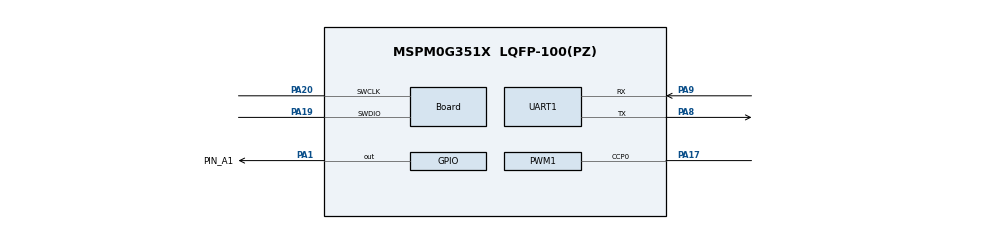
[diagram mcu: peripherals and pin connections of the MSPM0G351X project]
/**
 * @cliArgs --device "MSPM0G351X" --part "Default" --package "LQFP-100(PZ)" --product "mspm0_sdk@2.05.01.00"
 * @versions {"tool":"1.24.0+4110"}
 */

/**
 * Import the modules used in this configuration.
 */
const ADC12         = scripting.addModule("/ti/driverlib/ADC12", {}, false);
const ADC121        = ADC12.addInstance();
const ADC122        = ADC12.addInstance();
const Board         = scripting.addModule("/ti/driverlib/Board");
const DAC12         = scripting.addModule("/ti/driverlib/DAC12");
const DMA           = scripting.addModule("/ti/driverlib/DMA");
const GPIO          = scripting.addModule("/ti/driverlib/GPIO", {}, false);
const GPIO1         = GPIO.addInstance();
const GPIO2         = GPIO.addInstance();
const PWM           = scripting.addModule("/ti/driverlib/PWM", {}, false);
const PWM1          = PWM.addInstance();
const SYSCTL        = scripting.addModule("/ti/driverlib/SYSCTL");
const TIMER         = scripting.addModule("/ti/driverlib/TIMER", {}, false);
const TIMER1        = TIMER.addInstance();
const UART          = scripting.addModule("/ti/driverlib/UART", {}, false);
const UART1         = UART.addInstance();
const ProjectConfig = scripting.addModule("/ti/project_config/ProjectConfig");

/**
 * Write custom configuration values to the imported modules.
 */
const gate8  = system.clockTree["MFPCLKGATE"];
gate8.enable = true;

ADC121.$name                             = "ADC12_0";
ADC121.trigSrc                           = "DL_ADC12_TRIG_SRC_EVENT";
ADC121.subChanID                         = 1;
ADC121.hwDenominator                     = "DL_ADC12_HW_AVG_DEN_DIV_BY_128";
ADC121.adcMem0chansel                    = "DL_ADC12_INPUT_CHAN_2";
ADC121.configureDMA                      = true;
ADC121.enabledInterrupts                 = ["DL_ADC12_INTERRUPT_DMA_DONE"];
ADC121.repeatMode                        = true;
ADC121.enabledDMATriggers                = ["DL_ADC12_DMA_MEM0_RESULT_LOADED"];
ADC121.sampleTime0                       = "62.5ns";
ADC121.adcMem0trig                       = "DL_ADC12_TRIGGER_MODE_TRIGGER_NEXT";
ADC121.sampCnt                           = 1;
ADC121.powerDownMode                     = "DL_ADC12_POWER_DOWN_MODE_MANUAL";
ADC121.peripheral.$assign                = "ADC0";
ADC121.adcPin2Config.$name               = "ti_driverlib_gpio_GPIOPinGeneric0";
ADC121.DMA_CHANNEL.$name                 = "DMA_CH0";
ADC121.DMA_CHANNEL.srcLength             = "HALF_WORD";
ADC121.DMA_CHANNEL.dstLength             = "HALF_WORD";
ADC121.DMA_CHANNEL.addressMode           = "f2b";
ADC121.DMA_CHANNEL.configureTransferSize = true;
ADC121.DMA_CHANNEL.transferSize          = 1024;

ADC122.$name                             = "ADC12_1";
ADC122.trigSrc                           = "DL_ADC12_TRIG_SRC_EVENT";
ADC122.hwDenominator                     = "DL_ADC12_HW_AVG_DEN_DIV_BY_32";
ADC122.subChanID                         = 2;
ADC122.adcMem0chansel                    = "DL_ADC12_INPUT_CHAN_14";
ADC122.powerDownMode                     = "DL_ADC12_POWER_DOWN_MODE_MANUAL";
ADC122.sampleTime0                       = "62.5ns";
ADC122.enabledInterrupts                 = ["DL_ADC12_INTERRUPT_DMA_DONE"];
ADC122.configureDMA                      = true;
ADC122.adcMem0trig                       = "DL_ADC12_TRIGGER_MODE_TRIGGER_NEXT";
ADC122.sampCnt                           = 1;
ADC122.enabledDMATriggers                = ["DL_ADC12_DMA_MEM0_RESULT_LOADED"];
ADC122.repeatMode                        = true;
ADC122.peripheral.$assign                = "ADC1";
ADC122.peripheral.adcPin14.$assign       = "PB27";
ADC122.adcPin14Config.$name              = "ti_driverlib_gpio_GPIOPinGeneric1";
ADC122.DMA_CHANNEL.$name                 = "DMA_CH1";
ADC122.DMA_CHANNEL.srcLength             = "HALF_WORD";
ADC122.DMA_CHANNEL.dstLength             = "HALF_WORD";
ADC122.DMA_CHANNEL.addressMode           = "f2b";
ADC122.DMA_CHANNEL.configureTransferSize = true;
ADC122.DMA_CHANNEL.transferSize          = 1024;

Board.peripheral.$assign          = "DEBUGSS";
Board.peripheral.swclkPin.$assign = "PA20";
Board.peripheral.swdioPin.$assign = "PA19";

DAC12.dacAmplifier       = "ON";
DAC12.dacOutputPinEn     = true;
DAC12.dacSampleTimerEn   = true;
DAC12.dacFIFOTrigger     = "HWTRIG0";
DAC12.peripheral.$assign = "DAC0";
DAC12.OutPinConfig.$name = "ti_driverlib_gpio_GPIOPinGeneric5";

GPIO1.$name                           = "GPIO_AD9910";
GPIO1.associatedPins.create(12);
GPIO1.associatedPins[0].$name         = "PIN_RESET";
GPIO1.associatedPins[0].assignedPort  = "PORTB";
GPIO1.associatedPins[0].assignedPin   = "2";
GPIO1.associatedPins[1].$name         = "PIN_CS";
GPIO1.associatedPins[1].assignedPort  = "PORTA";
GPIO1.associatedPins[1].assignedPin   = "31";
GPIO1.associatedPins[2].$name         = "PIN_SCLK";
GPIO1.associatedPins[2].assignedPort  = "PORTA";
GPIO1.associatedPins[2].assignedPin   = "29";
GPIO1.associatedPins[3].$name         = "PIN_SDIO";
GPIO1.associatedPins[3].assignedPort  = "PORTC";
GPIO1.associatedPins[3].assignedPin   = "17";
GPIO1.associatedPins[4].$name         = "PIN_UPDATE";
GPIO1.associatedPins[4].assignedPort  = "PORTC";
GPIO1.associatedPins[4].assignedPin   = "26";
GPIO1.associatedPins[5].$name         = "PIN_PROFILE0";
GPIO1.associatedPins[5].assignedPort  = "PORTC";
GPIO1.associatedPins[5].assignedPin   = "27";
GPIO1.associatedPins[6].$name         = "PIN_PROFILE1";
GPIO1.associatedPins[6].assignedPort  = "PORTC";
GPIO1.associatedPins[6].assignedPin   = "7";
GPIO1.associatedPins[7].$name         = "PIN_PROFILE2";
GPIO1.associatedPins[7].assignedPort  = "PORTB";
GPIO1.associatedPins[7].assignedPin   = "17";
GPIO1.associatedPins[8].$name         = "PIN_DRCTL";
GPIO1.associatedPins[8].assignedPort  = "PORTB";
GPIO1.associatedPins[8].assignedPin   = "19";
GPIO1.associatedPins[9].assignedPort  = "PORTA";
GPIO1.associatedPins[9].assignedPin   = "21";
GPIO1.associatedPins[9].$name         = "PIN_DRHOLD";
GPIO1.associatedPins[10].assignedPort = "PORTA";
GPIO1.associatedPins[10].assignedPin  = "22";
GPIO1.associatedPins[10].$name        = "PIN_PWR";
GPIO1.associatedPins[11].$name        = "PIN_OSK";
GPIO1.associatedPins[11].assignedPort = "PORTB";
GPIO1.associatedPins[11].assignedPin  = "16";

GPIO2.$name                         = "GPIO_KEY";
GPIO2.associatedPins[0].$name       = "PIN_A1";
GPIO2.associatedPins[0].pin.$assign = "PA1";

PWM1.$name                      = "PWM_0";
PWM1.ccIndex                    = [0];
PWM1.PWM_CHANNEL_0.$name        = "ti_driverlib_pwm_PWMTimerCC0";
PWM1.ccp0PinConfig.$name        = "ti_driverlib_gpio_GPIOPinGeneric4";
PWM1.peripheral.$assign         = "TIMA1";
PWM1.peripheral.ccp0Pin.$assign = "PA17";

SYSCTL.forceDefaultClkConfig = true;
SYSCTL.MFPCLKEn              = true;

TIMER1.$name                       = "TIMER_0";
TIMER1.event1PublisherChannel      = 1;
TIMER1.event1ControllerInterruptEn = ["ZERO_EVENT"];
TIMER1.event2PublisherChannel      = 2;
TIMER1.event2ControllerInterruptEn = ["ZERO_EVENT"];
TIMER1.timerMode                   = "PERIODIC";
TIMER1.timerPeriod                 = "1us";
TIMER1.peripheral.$assign          = "TIMG0";

UART1.$name                    = "UART_0";
UART1.enabledInterrupts        = ["RX"];
UART1.peripheral.rxPin.$assign = "PA9";
UART1.peripheral.txPin.$assign = "PA8";
UART1.txPinConfig.$name        = "ti_driverlib_gpio_GPIOPinGeneric2";
UART1.rxPinConfig.$name        = "ti_driverlib_gpio_GPIOPinGeneric3";

ProjectConfig.migrationCondition = true;

/**
 * Pinmux solution for unlocked pins/peripherals. This ensures that minor changes to the automatic solver in a future
 * version of the tool will not impact the pinmux you originally saw.  These lines can be completely deleted in order to
 * re-solve from scratch.
 */
ADC121.peripheral.adcPin2.$suggestSolution     = "PA25";
ADC121.DMA_CHANNEL.peripheral.$suggestSolution = "DMA_CH1";
ADC122.DMA_CHANNEL.peripheral.$suggestSolution = "DMA_CH0";
DAC12.peripheral.OutPin.$suggestSolution       = "PA15";
GPIO1.associatedPins[0].pin.$suggestSolution   = "PB2";
GPIO1.associatedPins[1].pin.$suggestSolution   = "PA31";
GPIO1.associatedPins[2].pin.$suggestSolution   = "PA29";
GPIO1.associatedPins[3].pin.$suggestSolution   = "PC17";
GPIO1.associatedPins[4].pin.$suggestSolution   = "PC26";
GPIO1.associatedPins[5].pin.$suggestSolution   = "PC27";
GPIO1.associatedPins[6].pin.$suggestSolution   = "PC7";
GPIO1.associatedPins[7].pin.$suggestSolution   = "PB17";
GPIO1.associatedPins[8].pin.$suggestSolution   = "PB19";
GPIO1.associatedPins[9].pin.$suggestSolution   = "PA21";
GPIO1.associatedPins[10].pin.$suggestSolution  = "PA22";
GPIO1.associatedPins[11].pin.$suggestSolution  = "PB16";
SYSCTL.peripheral.$suggestSolution             = "SYSCTL";
UART1.peripheral.$suggestSolution              = "UART1";
